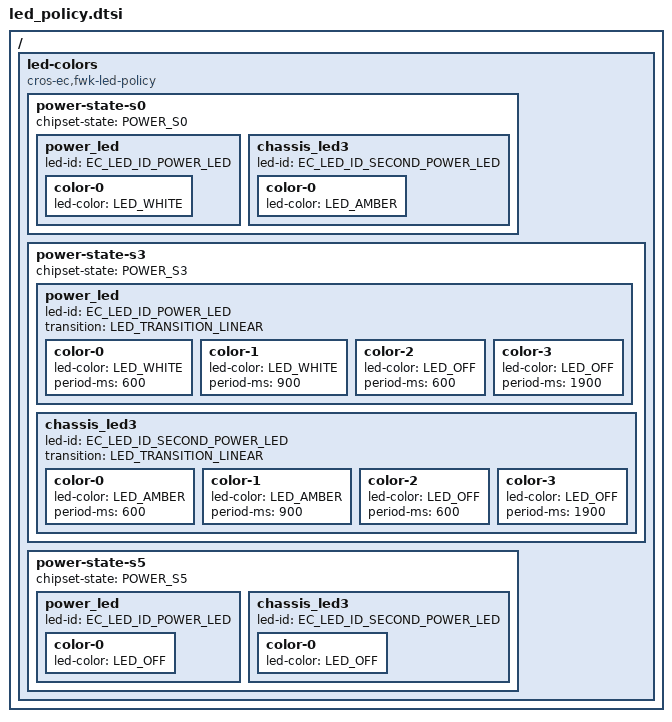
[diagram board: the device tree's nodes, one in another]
/* Copyright 2024 The ChromiumOS Authors
 * Use of this source code is governed by a BSD-style license that can be
 * found in the LICENSE file.
 */

/ {
	led-colors {
		compatible = "cros-ec,fwk-led-policy";

		power-state-s0 {
			chipset-state = "POWER_S0";

			power_led {
				led-id = "EC_LED_ID_POWER_LED";
				color-0 {
					led-color = "LED_WHITE";
				};
			};

			chassis_led3 {
				led-id = "EC_LED_ID_SECOND_POWER_LED";
				color-0 {
					led-color = "LED_AMBER";
				};
			};
		};

		power-state-s3 {
			chipset-state = "POWER_S3";

			power_led {
				led-id = "EC_LED_ID_POWER_LED";
				transition = "LED_TRANSITION_LINEAR";

				/* Fade time target 600ms (In, low to high) */
				color-0 {
					led-color = "LED_WHITE";
					period-ms = <600>;
				};
				/* Duration time target 900ms */
				color-1 {
					led-color = "LED_WHITE";
					period-ms = <900>;
				};
				/* Fade time target 600ms (Out, high to low) */
				color-2 {
					led-color = "LED_OFF";
					period-ms = <600>;
				};
				/* Interval time target 1900ms */
				color-3 {
					led-color = "LED_OFF";
					period-ms = <1900>;
				};
			};

			chassis_led3 {
				led-id = "EC_LED_ID_SECOND_POWER_LED";
				transition = "LED_TRANSITION_LINEAR";

				/* Fade time target 600ms (In, low to high) */
				color-0 {
					led-color = "LED_AMBER";
					period-ms = <600>;
				};
				/* Duration time target 900ms */
				color-1 {
					led-color = "LED_AMBER";
					period-ms = <900>;
				};
				/* Fade time target 600ms (Out, high to low) */
				color-2 {
					led-color = "LED_OFF";
					period-ms = <600>;
				};
				/* Interval time target 1900ms */
				color-3 {
					led-color = "LED_OFF";
					period-ms = <1900>;
				};
			};
		};

		power-state-s5 {
			chipset-state = "POWER_S5";

			power_led {
				led-id = "EC_LED_ID_POWER_LED";
				color-0 {
					led-color = "LED_OFF";
				};
			};

			chassis_led3 {
				led-id = "EC_LED_ID_SECOND_POWER_LED";
				color-0 {
					led-color = "LED_OFF";
				};
			};
		};
	};
};
